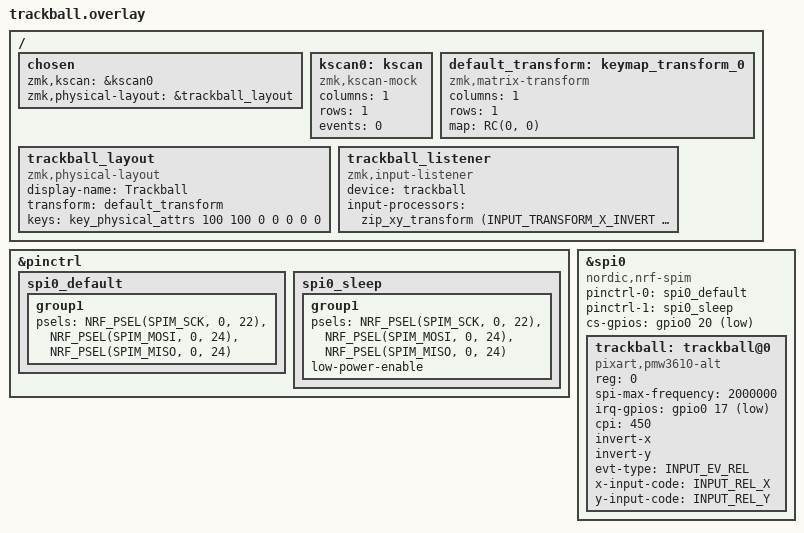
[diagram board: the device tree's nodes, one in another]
/*
 * Standalone PMW3610 trackball on a nice!nano.
 * Same SPI pins as boards/shields/charybdis/charybdis_3610.dtsi.
 *
 * nice!nano (USB up, chip facing you), left header:
 *   P0.24 / 024 / D5  SDIO  (MOSI and MISO share this one wire)
 *   P0.22 / 022 / D4  SCLK
 *   P0.20 / 020 / D3  nCS
 *   P0.17 / 017 / D2  MOTION
 * Right header:
 *   3.3V              VIN
 *   GND               GND
 * nRESET stays unconnected. Do not use RAW or 5V.
 */

#include <dt-bindings/zmk/matrix_transform.h>
#include <dt-bindings/zmk/input_transform.h>
#include <input/processors.dtsi>
#include <physical_layouts.dtsi>

#define INPUT_EV_REL 0x02
#define INPUT_REL_X 0x00
#define INPUT_REL_Y 0x01

/ {
    chosen {
        zmk,kscan = &kscan0;
        zmk,physical-layout = &trackball_layout;
    };

    kscan0: kscan {
        compatible = "zmk,kscan-mock";
        columns = <1>;
        rows = <1>;
        events = <0>;
    };

    default_transform: keymap_transform_0 {
        compatible = "zmk,matrix-transform";
        columns = <1>;
        rows = <1>;
        map = <RC(0, 0)>;
    };

    trackball_layout: trackball_layout {
        compatible = "zmk,physical-layout";
        display-name = "Trackball";
        transform = <&default_transform>;
        keys = <&key_physical_attrs 100 100 0 0 0 0 0>;
    };

    trackball_listener: trackball_listener {
        compatible = "zmk,input-listener";
        device = <&trackball>;
        input-processors = <&zip_xy_transform (INPUT_TRANSFORM_X_INVERT | INPUT_TRANSFORM_Y_INVERT | INPUT_TRANSFORM_XY_SWAP)>;
    };
};

&pinctrl {
    spi0_default: spi0_default {
        group1 {
            psels = <NRF_PSEL(SPIM_SCK, 0, 22)>,
                <NRF_PSEL(SPIM_MOSI, 0, 24)>,
                <NRF_PSEL(SPIM_MISO, 0, 24)>;
        };
    };

    spi0_sleep: spi0_sleep {
        group1 {
            psels = <NRF_PSEL(SPIM_SCK, 0, 22)>,
                <NRF_PSEL(SPIM_MOSI, 0, 24)>,
                <NRF_PSEL(SPIM_MISO, 0, 24)>;
            low-power-enable;
        };
    };
};

&spi0 {
    status = "okay";
    compatible = "nordic,nrf-spim";
    pinctrl-0 = <&spi0_default>;
    pinctrl-1 = <&spi0_sleep>;
    pinctrl-names = "default", "sleep";
    cs-gpios = <&gpio0 20 GPIO_ACTIVE_LOW>;

    trackball: trackball@0 {
        status = "okay";
        compatible = "pixart,pmw3610-alt";
        reg = <0>;
        spi-max-frequency = <2000000>;
        irq-gpios = <&gpio0 17 (GPIO_ACTIVE_LOW | GPIO_PULL_UP)>;
        cpi = <450>;
        invert-x;
        invert-y;
        evt-type = <INPUT_EV_REL>;
        x-input-code = <INPUT_REL_X>;
        y-input-code = <INPUT_REL_Y>;
    };
};
